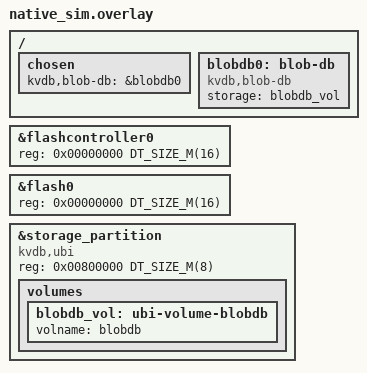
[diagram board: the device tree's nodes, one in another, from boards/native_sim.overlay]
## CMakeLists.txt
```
# Copyright (c) 2026
# SPDX-License-Identifier: Apache-2.0

cmake_minimum_required(VERSION 3.20.0)
find_package(Zephyr REQUIRED HINTS $ENV{ZEPHYR_BASE})
project(blob_db_contract_test)

# The model containers are the executable form of the L1 sufficiency proof
# (doc/layers/l1_model_container.md, l1_model_container_list.md). They are
# built here, not in lib/, because they are test/proof artifacts, not
# shipped code.
target_sources(app PRIVATE
	src/main.c
	src/model_container_map.c
	src/list.c
	src/model_container_list.c
)
target_include_directories(app PRIVATE src)
```

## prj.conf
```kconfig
CONFIG_ZTEST=y
# blob_db is switched on by the kvdb,blob-db node in boards/<board>.overlay.
CONFIG_BLOB_ROOTREG=y

# Compaction nests two 4 KB scratch buffers under a 4 KB bucket buffer;
# bump stacks to fit (same as the L1 unit suite).
CONFIG_MAIN_STACK_SIZE=32768
CONFIG_ZTEST_STACK_SIZE=32768
CONFIG_LOG=y
```

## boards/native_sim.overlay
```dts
/*
 * 16 MB sim-flash with an 8 MB storage_partition at offset 0x800000 — matches
 * the app and the L1 unit suite so blob_db sees the full multi-bucket layout.
 */

&flashcontroller0 {
	reg = <0x00000000 DT_SIZE_M(16)>;
};

&flash0 {
	reg = <0x00000000 DT_SIZE_M(16)>;
};

&storage_partition {
	/* A UBI device with one volume, which blob_db lives on. Keep
	 * "zephyr,mapped-partition": it is what makes the node a partition on
	 * native_sim.
	 */
	compatible = "kvdb,ubi", "zephyr,mapped-partition";
	reg = <0x00800000 DT_SIZE_M(8)>;

	volumes {
		blobdb_vol: ubi-volume-blobdb {
			volname = "blobdb";
		};
	};
};

/*
 * The blob_db store on the volume above. No "automount": the suite mounts,
 * formats and unmounts the store itself.
 */
/ {
	chosen {
		kvdb,blob-db = &blobdb0;
	};

	blobdb0: blob-db {
		compatible = "kvdb,blob-db";
		storage = <&blobdb_vol>;
	};
};
```

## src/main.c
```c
/*
 * Copyright (c) 2026
 * SPDX-License-Identifier: Apache-2.0
 *
 * L1 contract acceptance suite — drives the model container
 * (doc/layers/l1_model_container.md) end-to-end on native_sim to PROVE the
 * whole concept:
 *
 *   - single-integer reachability (P5): the container is re-opened after every
 *     remount from nothing but id = 1 — the root registry lives there and
 *     maps MC_ROOTREG_KEY to the list root;
 *   - crash-safety (P7): at every step of every reference-graph mutation, a
 *     crash + remount + recovery yields the complete old OR complete new
 *     mapping — never torn, never dangling;
 *   - no permanent leak (P7 must): after recovery the live blob count is
 *     EXACTLY the structural minimum (root + intent + 2 per entry).
 *
 * Crashes are injected at blob_db-operation boundaries: a mutation stops after
 * a chosen step (MC_STOPPED), then we unmount/remount and mc_open() runs
 * recovery from that exact point — matching the crash tables in §8.
 */

#include <errno.h>
#include <stdint.h>
#include <string.h>

#include <zephyr/ztest.h>

#include <app/lib/blob_db.h>
#include <app/lib/rootreg.h>

#include "model_container_map.h"

/* This suite is the container's CLIENT — it owns root-id persistence
 * (l1_root_registry.md §2) and registers the container under its key. */
#define MC_ROOTREG_KEY  ROOTREG_KEY(0x4d435f4d /* 'MC_M': model container, map */, 0)

/* Structural blob floor: the root registry (id = 1) + the list root + the
 * intent blob. Each live entry adds exactly two blobs (key + value). "No
 * leak" == live count matches this formula exactly. */
#define STRUCT_BLOBS  3

static void assert_no_leak(void)
{
	size_t entries;

	zassert_ok(mc_entry_count(&entries));
	zassert_equal(blob_db_count(), STRUCT_BLOBS + 2 * entries,
		      "leak: live blobs=%zu, expected=%zu (entries=%zu)",
		      blob_db_count(), STRUCT_BLOBS + 2 * entries, entries);
}

/* Client-side open: bootstrap the registry, resolve (or register) the
 * container's root id, hand it to the container. This is the l1½ pattern
 * every real client follows. */
static void open_container(void)
{
	uint64_t root;

	zassert_ok(rootreg_init());
	zassert_ok(rootreg_get_or_create(MC_ROOTREG_KEY, &root));
	zassert_ok(mc_open(root), "open/recovery failed");
}

/* Power-cut simulation: drop the mount and bring it back. The client
 * re-derives the entire container from id = 1 (registry -> list root) and
 * mc_open() runs intent recovery. */
static void crash_and_recover(void)
{
	zassert_ok(blob_db_unmount());
	zassert_ok(blob_db_mount());
	open_container();
}

/* Wipe to a virgin store and create an empty container. */
static void fresh_container(void)
{
	zassert_ok(blob_db_format());
	open_container();   /* virgin -> bootstrap registry + create */
}

static void before(void *f)
{
	ARG_UNUSED(f);
	mc_fail_after(MC_STEP_NONE, 0);
	mc_fail_key_read(0);
	blob_db_unmount();
	zassert_ok(blob_db_mount());
	fresh_container();
}

static void after(void *f)
{
	ARG_UNUSED(f);
	blob_db_unmount();
}

ZTEST_SUITE(blob_db_contract, NULL, NULL, before, after, NULL);

static int get_str(const char *key, char *out, size_t out_sz)
{
	size_t got;
	int rc = mc_get(key, out, out_sz, &got);

	if (rc == 0) {
		out[got] = '\0';
	}
	return rc;
}

/* --- basic flow (§3), completed mutations ------------------------------ */

ZTEST(blob_db_contract, test_empty_container)
{
	char buf[16];

	zassert_equal(get_str("foo", buf, sizeof(buf)), -ENOENT);
	assert_no_leak();
}

ZTEST(blob_db_contract, test_insert_lookup)
{
	zassert_ok(mc_set("foo", "bar", 3, MC_STEP_NONE));

	char buf[16];

	zassert_ok(get_str("foo", buf, sizeof(buf)));
	zassert_str_equal(buf, "bar");
	assert_no_leak();
}

ZTEST(blob_db_contract, test_overwrite)
{
	zassert_ok(mc_set("foo", "bar", 3, MC_STEP_NONE));
	zassert_ok(mc_set("foo", "bazzz", 5, MC_STEP_NONE));

	char buf[16];

	zassert_ok(get_str("foo", buf, sizeof(buf)));
	zassert_str_equal(buf, "bazzz");
	assert_no_leak();   /* old value blob reclaimed — count unchanged */
}

ZTEST(blob_db_contract, test_delete)
{
	zassert_ok(mc_set("foo", "bar", 3, MC_STEP_NONE));
	zassert_ok(mc_del("foo", MC_STEP_NONE));

	char buf[16];

	zassert_equal(get_str("foo", buf, sizeof(buf)), -ENOENT);
	assert_no_leak();   /* back to root + intent only */
}

/* --- single-integer reachability across remount ------------------------ */

ZTEST(blob_db_contract, test_multikey_persist_and_reopen)
{
	zassert_ok(mc_set("alpha", "1", 1, MC_STEP_NONE));
	zassert_ok(mc_set("beta", "22", 2, MC_STEP_NONE));
	zassert_ok(mc_set("gamma", "333", 3, MC_STEP_NONE));

	/* Reboot: the ONLY thing that persists is the integer 1. */
	crash_and_recover();

	char buf[16];

	zassert_ok(get_str("alpha", buf, sizeof(buf)));
	zassert_str_equal(buf, "1");
	zassert_ok(get_str("beta", buf, sizeof(buf)));
	zassert_str_equal(buf, "22");
	zassert_ok(get_str("gamma", buf, sizeof(buf)));
	zassert_str_equal(buf, "333");

	size_t entries;

	zassert_ok(mc_entry_count(&entries));
	zassert_equal(entries, 3);
	assert_no_leak();
}

/* --- crash tables (§8): recovery is correct AND leak-free -------------- */

struct crash_case {
	enum mc_crash_point cp;
	bool committed;
};

/* §8.1 Insert: committed once the list image is swapped (COMMIT). */
ZTEST(blob_db_contract, test_insert_crash_table)
{
	const struct crash_case cases[] = {
		{ MC_STEP_STAGE,   false },
		{ MC_STEP_PREPARE, false },
		{ MC_STEP_COMMIT,  true  },
		{ MC_STEP_CLEANUP, true  },
		{ MC_STEP_NONE,    true  },
	};

	for (size_t i = 0; i < ARRAY_SIZE(cases); i++) {
		fresh_container();

		int rc = mc_set("foo", "bar", 3, cases[i].cp);

		if (cases[i].cp == MC_STEP_NONE) {
			zassert_ok(rc);
		} else {
			zassert_equal(rc, MC_STOPPED, "case %zu", i);
		}

		crash_and_recover();

		char buf[16];

		if (cases[i].committed) {
			zassert_ok(get_str("foo", buf, sizeof(buf)),
				   "case %zu should be committed", i);
			zassert_str_equal(buf, "bar");
		} else {
			zassert_equal(get_str("foo", buf, sizeof(buf)), -ENOENT,
				      "case %zu should be rolled back", i);
		}
		assert_no_leak();   /* prepared-but-abandoned blobs reclaimed */
	}
}

/* §8.2 Overwrite (genuine value replacement): committed at COMMIT. */
ZTEST(blob_db_contract, test_overwrite_crash_table)
{
	const struct crash_case cases[] = {
		{ MC_STEP_STAGE,   false },
		{ MC_STEP_PREPARE, false },
		{ MC_STEP_COMMIT,  true  },
		{ MC_STEP_CLEANUP, true  },
		{ MC_STEP_NONE,    true  },
	};

	for (size_t i = 0; i < ARRAY_SIZE(cases); i++) {
		fresh_container();
		zassert_ok(mc_set("foo", "bar", 3, MC_STEP_NONE));   /* seed */

		int rc = mc_set("foo", "bazzz", 5, cases[i].cp);

		if (cases[i].cp == MC_STEP_NONE) {
			zassert_ok(rc);
		} else {
			zassert_equal(rc, MC_STOPPED, "case %zu", i);
		}

		crash_and_recover();

		char buf[16];

		zassert_ok(get_str("foo", buf, sizeof(buf)));
		zassert_str_equal(buf, cases[i].committed ? "bazzz" : "bar");

		size_t entries;

		zassert_ok(mc_entry_count(&entries));
		zassert_equal(entries, 1, "case %zu entries", i);
		assert_no_leak();   /* exactly one value blob survives */
	}
}

/* --- full-lifecycle cleanup: destroy + unregister ----------------------- */

/* Tear-down leaves the store at the absolute floor — ONLY the (empty-again)
 * registry survives — and a later open under the same key starts a brand-new
 * container on a fresh id (dead ids are never reused). */
ZTEST(blob_db_contract, test_destroy_and_unregister_cleanup)
{
	zassert_ok(mc_set("alpha", "1", 1, MC_STEP_NONE));
	zassert_ok(mc_set("beta", "22", 2, MC_STEP_NONE));
	zassert_ok(mc_set("gamma", "333", 3, MC_STEP_NONE));

	uint64_t old_root;

	zassert_ok(rootreg_get(MC_ROOTREG_KEY, &old_root));

	/* Cleanup: unset all keys + structure, then drop the registry entry
	 * (teardown BEFORE unregistration — registry §8). */
	zassert_ok(mc_destroy());
	zassert_ok(rootreg_unregister(MC_ROOTREG_KEY));

	/* Only the registry blob remains, and the container is truly gone. */
	zassert_equal(blob_db_count(), 1,
		      "want registry only, got %zu blobs", blob_db_count());
	zassert_false(blob_db_exists(old_root));

	char buf[8];

	zassert_equal(mc_get("alpha", buf, sizeof(buf), NULL), -ENODEV,
		      "container must be closed after destroy");

	/* Same key, fresh life: a new root id, an empty container. */
	open_container();

	uint64_t new_root;

	zassert_ok(rootreg_get(MC_ROOTREG_KEY, &new_root));
	zassert_not_equal(new_root, old_root, "dead ids must not be reused");
	zassert_equal(get_str("alpha", buf, sizeof(buf)), -ENOENT);
	assert_no_leak();
}

/* Destroy is re-runnable: a "crash" between destroy and unregister just
 * means the next open finds the registered id dead… which must NOT happen
 * silently — so the client contract is destroy-then-unregister with no
 * mutation in between. This test pins the safe rerun path instead: destroy
 * on an already-half-torn container (simulated by a double destroy cycle). */
ZTEST(blob_db_contract, test_destroy_empty_container)
{
	zassert_ok(mc_destroy());   /* no entries — deletes intent + root */
	zassert_ok(rootreg_unregister(MC_ROOTREG_KEY));
	zassert_equal(blob_db_count(), 1);

	open_container();           /* fresh container, fresh id */
	assert_no_leak();
}

/* --- create / destroy interrupted between root and intent ------------- */

/* The intent id the list root names, read straight from the root payload. */
static uint64_t root_intent_id(uint64_t root)
{
	uint8_t buf[CONFIG_BLOB_DB_MAX_PAYLOAD_LEN];
	size_t got;
	uint64_t id;

	zassert_ok(blob_db_get(root, buf, sizeof(buf), &got));
	memcpy(&id, buf, sizeof(id));
	return id;
}

/* Create commits the root first, naming an intent id it has not bound yet.
 * A crash right there must leave no residue: the next open gives the list
 * a fresh intent blob and never binds the one the root named. */
ZTEST(blob_db_contract, test_create_crash_before_intent)
{
	uint64_t root;

	zassert_ok(blob_db_format());
	zassert_ok(rootreg_init());
	zassert_ok(rootreg_get_or_create(MC_ROOTREG_KEY, &root));

	/* The state create leaves when it stops after its commit: an empty
	 * list naming an intent id that was allocated and never bound. */
	uint64_t unbound = blob_db_alloc_id();
	uint8_t img[12] = { 0 };

	zassert_not_equal(unbound, BLOB_DB_INVALID_ID);
	memcpy(img, &unbound, sizeof(unbound));
	zassert_ok(blob_db_update(root, img, sizeof(img)));

	crash_and_recover();

	zassert_false(blob_db_exists(unbound), "named intent id was bound");
	zassert_not_equal(root_intent_id(root), unbound);
	assert_no_leak();

	char buf[16];

	zassert_ok(mc_set("foo", "bar", 3, MC_STEP_NONE));
	zassert_ok(get_str("foo", buf, sizeof(buf)));
	zassert_str_equal(buf, "bar");
	assert_no_leak();
}

/* Destroy deletes the intent before the root. A crash between the two must
 * not leave the container unopenable: open repairs it and destroy reruns. */
ZTEST(blob_db_contract, test_destroy_crash_before_root)
{
	uint64_t root;

	zassert_ok(mc_set("foo", "bar", 3, MC_STEP_NONE));
	zassert_ok(rootreg_get(MC_ROOTREG_KEY, &root));

	/* Intent gone, root still bound — as when destroy stops between the
	 * two. (Destroy would have deleted the entries too; open does not
	 * care, and the rerun tolerates either.) */
	zassert_ok(blob_db_delete(root_intent_id(root)));

	crash_and_recover();

	zassert_ok(mc_destroy());
	zassert_ok(rootreg_unregister(MC_ROOTREG_KEY));
	zassert_equal(blob_db_count(), 1,
		      "want registry only, got %zu blobs", blob_db_count());
}

/* --- an unreadable key is not an absent key ---------------------------- */

/* Lookups skip only a key that answers -ENOENT. Any other read error
 * reaches the caller before anything is written — above all it never
 * turns an overwrite into the insert of a second entry for the key. */
ZTEST(blob_db_contract, test_key_read_error_propagates)
{
	char buf[16];
	size_t n;

	zassert_ok(mc_set("foo", "bar", 3, MC_STEP_NONE));

	mc_fail_key_read(-EIO);
	zassert_equal(mc_set("foo", "baz", 3, MC_STEP_NONE), -EIO);
	zassert_ok(mc_entry_count(&n));
	zassert_equal(n, 1, "an unreadable key was inserted again");
	zassert_ok(get_str("foo", buf, sizeof(buf)));
	zassert_str_equal(buf, "bar");
	assert_no_leak();

	mc_fail_key_read(-EIO);
	zassert_equal(get_str("foo", buf, sizeof(buf)), -EIO);

	mc_fail_key_read(-EIO);
	zassert_equal(mc_del("foo", MC_STEP_NONE), -EIO);
	zassert_ok(get_str("foo", buf, sizeof(buf)));
	zassert_str_equal(buf, "bar");
	assert_no_leak();
}

/* --- direct id-1 binding ------------------------------------------------ */

/* A client without a registry may build the list at BLOB_DB_ROOT_ID itself.
 * That id is never unbound — a fresh store binds it empty — so an empty
 * payload must read as "create now", and destroy must reset it to empty
 * instead of deleting it. */
ZTEST(blob_db_contract, test_direct_root_binding)
{
	char buf[16];

	zassert_ok(blob_db_format());   /* id 1 bound, empty; no registry */
	zassert_ok(mc_open(BLOB_DB_ROOT_ID));
	zassert_ok(mc_set("foo", "bar", 3, MC_STEP_NONE));

	zassert_ok(blob_db_unmount());
	zassert_ok(blob_db_mount());
	zassert_ok(mc_open(BLOB_DB_ROOT_ID));
	zassert_ok(get_str("foo", buf, sizeof(buf)));
	zassert_str_equal(buf, "bar");
	/* id 1 (list root) + intent + key + value */
	zassert_equal(blob_db_count(), 4, "got %zu blobs", blob_db_count());

	zassert_ok(mc_destroy());
	zassert_true(blob_db_exists(BLOB_DB_ROOT_ID));
	zassert_equal(blob_db_count(), 1, "got %zu blobs", blob_db_count());

	zassert_ok(mc_open(BLOB_DB_ROOT_ID));   /* fresh container */
	zassert_equal(get_str("foo", buf, sizeof(buf)), -ENOENT);
	zassert_equal(blob_db_count(), 2, "got %zu blobs", blob_db_count());
}

/* A root whose payload is not shaped like a list is refused, and leaves
 * the container closed. */
ZTEST(blob_db_contract, test_malformed_root_refused)
{
	uint64_t id = blob_db_alloc_id();
	char buf[16];

	zassert_not_equal(id, BLOB_DB_INVALID_ID);
	zassert_ok(blob_db_update(id, "xyz", 3));
	zassert_equal(mc_open(id), -EIO);
	zassert_equal(get_str("foo", buf, sizeof(buf)), -ENODEV);
}

/* --- recovery touches only the ids the intent names -------------------- */

/* A second structure in the same store, registered under its own key. */
#define OTHER_ROOTREG_KEY  ROOTREG_KEY(0x4f544852 /* 'OTHR' */, 0)

/* Firmware opens stores lazily, so after a reboot another client may
 * allocate and bind blobs BEFORE this container's mc_open() runs recovery.
 * Those blobs have ids above anything the interrupted mutation allocated,
 * and the container's list does not reference them. Rolling back must still
 * leave them alone: recovery deletes only what its intent named. */
ZTEST(blob_db_contract, test_rollback_spares_other_store)
{
	zassert_equal(mc_set("foo", "bar", 3, MC_STEP_PREPARE), MC_STOPPED);

	/* Reboot, but let another store come up and write first. */
	zassert_ok(blob_db_unmount());
	zassert_ok(blob_db_mount());
	zassert_ok(rootreg_init());

	uint64_t other;

	zassert_ok(rootreg_get_or_create(OTHER_ROOTREG_KEY, &other));
	zassert_ok(blob_db_update(other, "cfg", 3));

	/* Only now is the container opened, and its insert rolled back. */
	open_container();

	char buf[16];
	size_t got;

	zassert_equal(get_str("foo", buf, sizeof(buf)), -ENOENT);
	zassert_ok(blob_db_get(other, buf, sizeof(buf), &got),
		   "recovery deleted another store's blob");
	zassert_equal(got, 3);
	zassert_mem_equal(buf, "cfg", 3);

	/* No leak either: the container's floor plus the other store's root. */
	zassert_equal(blob_db_count(), STRUCT_BLOBS + 1,
		      "live blobs=%zu, expected=%d", blob_db_count(),
		      STRUCT_BLOBS + 1);
}

/* A full list is refused before anything is written: nothing to undo, and
 * nothing left behind. */
ZTEST(blob_db_contract, test_failed_set_leaks_nothing)
{
	char key[8];
	int rc;
	size_t n = 0;

	do {
		snprintk(key, sizeof(key), "k%zu", n++);
		rc = mc_set(key, "v", 1, MC_STEP_NONE);
	} while (rc == 0);

	zassert_equal(rc, -ENOSPC);
	assert_no_leak();

	/* The container still works, and a later mutation leaks nothing. */
	zassert_ok(mc_del("k0", MC_STEP_NONE));
	zassert_ok(mc_set("late", "v", 1, MC_STEP_NONE));
	assert_no_leak();
}

/* --- clean failures (§5 abort path), no remount ----------------------- */

/* A step that fails without a power cut aborts through the same recovery a
 * remount runs: rolled back (error returned) before COMMIT, finished (0
 * returned) after it. Either way nothing leaks, without remounting. */
ZTEST(blob_db_contract, test_failed_mutation_aborts_cleanly)
{
	const struct crash_case cases[] = {
		{ MC_STEP_STAGE,   false },
		{ MC_STEP_PREPARE, false },
		{ MC_STEP_COMMIT,  true  },
		{ MC_STEP_CLEANUP, true  },
	};
	char buf[16];

	for (size_t i = 0; i < ARRAY_SIZE(cases); i++) {
		const bool done = cases[i].committed;

		/* Insert. */
		fresh_container();
		mc_fail_after(cases[i].cp, -EIO);
		zassert_equal(mc_set("foo", "bar", 3, MC_STEP_NONE),
			      done ? 0 : -EIO, "insert case %zu", i);
		if (done) {
			zassert_ok(get_str("foo", buf, sizeof(buf)));
			zassert_str_equal(buf, "bar");
		} else {
			zassert_equal(get_str("foo", buf, sizeof(buf)), -ENOENT);
		}
		assert_no_leak();

		/* Overwrite. */
		fresh_container();
		zassert_ok(mc_set("foo", "bar", 3, MC_STEP_NONE));
		mc_fail_after(cases[i].cp, -EIO);
		zassert_equal(mc_set("foo", "bazzz", 5, MC_STEP_NONE),
			      done ? 0 : -EIO, "overwrite case %zu", i);
		zassert_ok(get_str("foo", buf, sizeof(buf)));
		zassert_str_equal(buf, done ? "bazzz" : "bar");
		assert_no_leak();

		/* Delete. */
		fresh_container();
		zassert_ok(mc_set("foo", "bar", 3, MC_STEP_NONE));
		mc_fail_after(cases[i].cp, -EIO);
		zassert_equal(mc_del("foo", MC_STEP_NONE),
			      done ? 0 : -EIO, "delete case %zu", i);
		zassert_equal(get_str("foo", buf, sizeof(buf)),
			      done ? -ENOENT : 0);
		assert_no_leak();

		/* The container keeps working after the abort. */
		zassert_ok(mc_set("next", "v", 1, MC_STEP_NONE));
		assert_no_leak();
	}
}

/* An interrupted mutation that nobody recovered yet (no remount) is
 * finished by the next mutation before it stages, and by destroy before it
 * deletes, so its prepared blobs are never stranded. */
ZTEST(blob_db_contract, test_staged_intent_finished_before_next_mutation)
{
	zassert_equal(mc_set("foo", "bar", 3, MC_STEP_PREPARE), MC_STOPPED);
	zassert_ok(mc_set("other", "v", 1, MC_STEP_NONE));

	char buf[16];

	zassert_equal(get_str("foo", buf, sizeof(buf)), -ENOENT);
	assert_no_leak();

	zassert_equal(mc_set("foo", "bar", 3, MC_STEP_PREPARE), MC_STOPPED);
	zassert_ok(mc_destroy());
	zassert_ok(rootreg_unregister(MC_ROOTREG_KEY));
	zassert_equal(blob_db_count(), 1,
		      "want registry only, got %zu blobs", blob_db_count());
}

/* §8.3 Delete: committed once the entry is unlinked (COMMIT). */
ZTEST(blob_db_contract, test_delete_crash_table)
{
	const struct crash_case cases[] = {
		{ MC_STEP_STAGE,   false },
		{ MC_STEP_PREPARE, false },
		{ MC_STEP_COMMIT,  true  },
		{ MC_STEP_CLEANUP, true  },
		{ MC_STEP_NONE,    true  },
	};

	for (size_t i = 0; i < ARRAY_SIZE(cases); i++) {
		fresh_container();
		zassert_ok(mc_set("foo", "bar", 3, MC_STEP_NONE));   /* seed */

		int rc = mc_del("foo", cases[i].cp);

		if (cases[i].cp == MC_STEP_NONE) {
			zassert_ok(rc);
		} else {
			zassert_equal(rc, MC_STOPPED, "case %zu", i);
		}

		crash_and_recover();

		char buf[16];

		if (cases[i].committed) {
			zassert_equal(get_str("foo", buf, sizeof(buf)), -ENOENT,
				      "case %zu should be deleted", i);
		} else {
			zassert_ok(get_str("foo", buf, sizeof(buf)),
				   "case %zu should be intact", i);
			zassert_str_equal(buf, "bar");
		}
		assert_no_leak();   /* orphaned key/value blobs reclaimed */
	}
}
```

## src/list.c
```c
/*
 * Copyright (c) 2026
 * SPDX-License-Identifier: Apache-2.0
 *
 * L1 contract acceptance suite, second model container: the doubly linked
 * list (doc/layers/l1_model_container_list.md). Same proof as main.c, for a
 * structure whose every structural mutation changes two existing i-nodes:
 *
 *   - single-integer reachability (P5): reopened after every remount from
 *     id = 1, where the root registry maps MCL_ROOTREG_KEY to the list root;
 *   - crash-safety (P7): at every step of every insert and remove, a crash +
 *     remount + recovery yields the complete old OR complete new list, read
 *     forwards AND backwards — the back chain always mirrors the forward one;
 *   - no permanent leak (P7 must): after recovery the live blob count is
 *     EXACTLY root registry + root + intent + 2 per node.
 */

#include <errno.h>
#include <stdint.h>
#include <string.h>

#include <zephyr/ztest.h>

#include <app/lib/blob_db.h>
#include <app/lib/rootreg.h>

#include "model_container_list.h"

#define MCL_ROOTREG_KEY  ROOTREG_KEY(0x4d435f4c /* 'MC_L': model container, list */, 0)
#define OTHER_ROOTREG_KEY  ROOTREG_KEY(0x4f544852 /* 'OTHR' */, 0)

/* Root registry (id = 1) + list root + intent. Each node adds two blobs:
 * the node and its value. */
#define STRUCT_BLOBS  3

static void open_list(void)
{
	uint64_t root;

	zassert_ok(rootreg_init());
	zassert_ok(rootreg_get_or_create(MCL_ROOTREG_KEY, &root));
	zassert_ok(mcl_open(root), "open/recovery failed");
}

static void crash_and_recover(void)
{
	zassert_ok(blob_db_unmount());
	zassert_ok(blob_db_mount());
	open_list();
}

static void fresh_list(void)
{
	mcl_fail_after(MCL_STEP_NONE, 0);
	zassert_ok(blob_db_format());
	open_list();
}

static void before(void *f)
{
	ARG_UNUSED(f);
	blob_db_unmount();
	zassert_ok(blob_db_mount());
	fresh_list();
}

static void after(void *f)
{
	ARG_UNUSED(f);
	blob_db_unmount();
}

ZTEST_SUITE(blob_db_contract_list, NULL, NULL, before, after, NULL);

/* Values in these tests are single characters, so a whole list reads as a
 * string: "abc" is a -> b -> c. */
static char val_of(uint64_t id)
{
	char v[4];
	size_t got;

	zassert_ok(mcl_get(id, v, sizeof(v), &got));
	zassert_equal(got, 1);
	return v[0];
}

/* The list reads `want` forwards and backwards, the back chain mirrors the
 * forward one node by node, and nothing leaked. */
static void expect_list(const char *want, const char *ctx)
{
	size_t n = strlen(want);
	size_t count;
	uint64_t id = 0;

	for (size_t i = 0; i < n; i++) {
		zassert_ok(mcl_next(id, &id));
		zassert_not_equal(id, 0, "%s: list ends at %zu, want \"%s\"",
				  ctx, i, want);
		zassert_equal(val_of(id), want[i], "%s: forward [%zu], want \"%s\"",
			      ctx, i, want);
	}
	zassert_ok(mcl_next(id, &id));
	zassert_equal(id, 0, "%s: list longer than \"%s\"", ctx, want);

	for (size_t i = n; i-- > 0;) {
		zassert_ok(mcl_prev(id, &id));
		zassert_not_equal(id, 0, "%s: back chain ends early", ctx);
		zassert_equal(val_of(id), want[i], "%s: backward [%zu], want \"%s\"",
			      ctx, i, want);
	}
	zassert_ok(mcl_prev(id, &id));
	zassert_equal(id, 0, "%s: back chain longer than \"%s\"", ctx, want);

	zassert_ok(mcl_check(&count), "%s: links disagree", ctx);
	zassert_equal(count, n);
	zassert_equal(blob_db_count(), STRUCT_BLOBS + 2 * n,
		      "%s: leak: live blobs=%zu, expected=%zu", ctx,
		      blob_db_count(), STRUCT_BLOBS + 2 * n);
}

/* Append each character of `vals` as a node; ids[i] is the i-th node. */
static void seed(const char *vals, uint64_t *ids)
{
	for (size_t i = 0; vals[i] != '\0'; i++) {
		zassert_ok(mcl_insert_before(0, &vals[i], 1, &ids[i],
					     MCL_STEP_NONE));
	}
}

/* --- basic operations ------------------------------------------------- */

ZTEST(blob_db_contract_list, test_empty_list)
{
	uint64_t id;

	zassert_ok(mcl_next(0, &id));
	zassert_equal(id, 0);
	zassert_ok(mcl_prev(0, &id));
	zassert_equal(id, 0);
	expect_list("", "empty");
}

ZTEST(blob_db_contract_list, test_insert_everywhere)
{
	uint64_t ids[3];
	uint64_t x;

	seed("abc", ids);                       /* push_back x3 */
	expect_list("abc", "seed");
	zassert_ok(mcl_insert_after(0, "z", 1, NULL, MCL_STEP_NONE));
	expect_list("zabc", "push_front");
	zassert_ok(mcl_insert_after(ids[0], "x", 1, &x, MCL_STEP_NONE));
	expect_list("zaxbc", "insert_after a");
	zassert_ok(mcl_insert_before(ids[2], "y", 1, NULL, MCL_STEP_NONE));
	expect_list("zaxbyc", "insert_before c");
	zassert_ok(mcl_insert_after(ids[2], "w", 1, NULL, MCL_STEP_NONE));
	expect_list("zaxbycw", "insert_after tail");
	zassert_ok(mcl_insert_before(x, "v", 1, NULL, MCL_STEP_NONE));
	expect_list("zavxbycw", "insert_before x");
}

ZTEST(blob_db_contract_list, test_remove_everywhere)
{
	uint64_t ids[5];

	seed("abcde", ids);
	zassert_ok(mcl_remove(ids[2], MCL_STEP_NONE));
	expect_list("abde", "remove middle");
	zassert_ok(mcl_remove(ids[0], MCL_STEP_NONE));
	expect_list("bde", "remove head");
	zassert_ok(mcl_remove(ids[4], MCL_STEP_NONE));
	expect_list("bd", "remove tail");
	zassert_ok(mcl_remove(ids[1], MCL_STEP_NONE));
	zassert_ok(mcl_remove(ids[3], MCL_STEP_NONE));
	expect_list("", "remove only");

	/* A removed node is no handle any more. */
	zassert_equal(mcl_remove(ids[3], MCL_STEP_NONE), -ENOENT);
	zassert_equal(mcl_insert_after(ids[3], "q", 1, NULL, MCL_STEP_NONE),
		      -ENOENT);
	expect_list("", "after stale handles");
}

/* Overwriting a value does not change the reference graph: one in-place
 * update, no new blob, nothing to recover. */
ZTEST(blob_db_contract_list, test_set_in_place)
{
	uint64_t ids[3];

	seed("abc", ids);
	zassert_ok(mcl_set(ids[1], "B", 1));
	expect_list("aBc", "set");
}

ZTEST(blob_db_contract_list, test_persist_and_reopen)
{
	uint64_t ids[4];

	seed("abcd", ids);
	zassert_ok(mcl_remove(ids[1], MCL_STEP_NONE));

	crash_and_recover();   /* only the integer 1 persists */

	expect_list("acd", "reopen");
	zassert_ok(mcl_insert_after(ids[0], "b", 1, NULL, MCL_STEP_NONE));
	expect_list("abcd", "after reopen");
}

/* A node id from another structure, or the list's own root, is not a node
 * of this list: writes refuse it and change nothing. */
ZTEST(blob_db_contract_list, test_foreign_ids_refused)
{
	uint64_t ids[2];
	uint64_t root;
	uint64_t other;
	/* Shaped like a node, and claiming to follow the head. */
	uint64_t fake[3];

	seed("ab", ids);
	zassert_ok(rootreg_get(MCL_ROOTREG_KEY, &root));
	zassert_ok(rootreg_get_or_create(OTHER_ROOTREG_KEY, &other));
	fake[0] = ids[0];
	fake[1] = ids[1];
	fake[2] = ids[1];
	zassert_ok(blob_db_update(other, fake, sizeof(fake)));

	zassert_equal(mcl_remove(other, MCL_STEP_NONE), -ENOENT);
	zassert_equal(mcl_remove(root, MCL_STEP_NONE), -ENOENT);
	zassert_equal(mcl_insert_after(other, "x", 1, NULL, MCL_STEP_NONE),
		      -ENOENT);
	zassert_equal(mcl_set(other, "x", 1), -ENOENT);

	zassert_ok(rootreg_unregister(OTHER_ROOTREG_KEY));
	zassert_ok(blob_db_delete(other));
	expect_list("ab", "foreign");
}

/* --- crash tables (§6): recovery is correct AND leak-free -------------- */

enum op_kind { INS_AFTER, INS_BEFORE, REMOVE };

/* One structural mutation: on a list seeded with `seed`, insert "n" next to
 * (or remove) seed node `at` (-1: the root's end). */
struct op_case {
	const char *name;
	const char *seed;
	enum op_kind kind;
	int at;
	const char *after;
};

static const struct op_case ops[] = {
	{ "push_front empty", "",    INS_AFTER,  -1, "n"    },
	{ "push_front",       "abc", INS_AFTER,  -1, "nabc" },
	{ "insert_after mid", "abc", INS_AFTER,   0, "anbc" },
	{ "insert_before",    "abc", INS_BEFORE,  2, "abnc" },
	{ "push_back",        "abc", INS_BEFORE, -1, "abcn" },
	{ "remove head",      "abc", REMOVE,      0, "bc"   },
	{ "remove mid",       "abc", REMOVE,      1, "ac"   },
	{ "remove tail",      "abc", REMOVE,      2, "ab"   },
	{ "remove only",      "a",   REMOVE,      0, ""     },
};

/* An insert that returns 0 hands back the new node's id, also when it
 * finished through the abort path: check it names the "n" node. */
static int run_op(const struct op_case *op, const uint64_t *ids,
		  enum mcl_crash_point cp)
{
	uint64_t at = op->at < 0 ? 0 : ids[op->at];
	uint64_t nid = 0;
	int rc;

	switch (op->kind) {
	case INS_AFTER:
		rc = mcl_insert_after(at, "n", 1, &nid, cp);
		break;
	case INS_BEFORE:
		rc = mcl_insert_before(at, "n", 1, &nid, cp);
		break;
	default:
		return mcl_remove(at, cp);
	}
	if (rc == 0) {
		zassert_equal(val_of(nid), 'n', "%s: wrong id handed back",
			      op->name);
	}
	return rc;
}

struct crash_case {
	enum mcl_crash_point cp;
	bool committed;
};

/* Committed once the forward link is swapped (COMMIT). */
static const struct crash_case points[] = {
	{ MCL_STEP_STAGE,   false },
	{ MCL_STEP_PREPARE, false },
	{ MCL_STEP_COMMIT,  true  },
	{ MCL_STEP_REPAIR,  true  },
	{ MCL_STEP_CLEANUP, true  },
	{ MCL_STEP_NONE,    true  },
};

ZTEST(blob_db_contract_list, test_crash_table)
{
	for (size_t i = 0; i < ARRAY_SIZE(ops); i++) {
		for (size_t j = 0; j < ARRAY_SIZE(points); j++) {
			uint64_t ids[3];
			char ctx[48];

			snprintk(ctx, sizeof(ctx), "%s, crash point %d",
				 ops[i].name, points[j].cp);
			fresh_list();
			seed(ops[i].seed, ids);

			int rc = run_op(&ops[i], ids, points[j].cp);

			zassert_equal(rc, points[j].cp == MCL_STEP_NONE ?
					  0 : MCL_STOPPED, "%s: rc %d", ctx, rc);

			crash_and_recover();
			expect_list(points[j].committed ? ops[i].after :
				    ops[i].seed, ctx);
		}
	}
}

/* --- clean failures (abort path), no remount -------------------------- */

ZTEST(blob_db_contract_list, test_failed_mutation_aborts_cleanly)
{
	for (size_t i = 0; i < ARRAY_SIZE(ops); i++) {
		for (size_t j = 0; j < ARRAY_SIZE(points); j++) {
			uint64_t ids[3];
			char ctx[48];

			if (points[j].cp == MCL_STEP_NONE) {
				continue;
			}
			snprintk(ctx, sizeof(ctx), "%s, fail after %d",
				 ops[i].name, points[j].cp);
			fresh_list();
			seed(ops[i].seed, ids);

			mcl_fail_after(points[j].cp, -EIO);
			zassert_equal(run_op(&ops[i], ids, MCL_STEP_NONE),
				      points[j].committed ? 0 : -EIO, "%s", ctx);
			expect_list(points[j].committed ? ops[i].after :
				    ops[i].seed, ctx);

			/* The list keeps working after the abort. */
			size_t len = strlen(points[j].committed ?
					    ops[i].after : ops[i].seed);
			size_t count;

			zassert_ok(mcl_insert_before(0, "t", 1, NULL,
						     MCL_STEP_NONE));
			zassert_ok(mcl_check(&count));
			zassert_equal(count, len + 1, "%s", ctx);
		}
	}
}

/* --- the two chains between COMMIT and REPAIR -------------------------- */

/* The forward chain is right at every instant: before the commit it does
 * not show the new node, after it it does — with no recovery run. The back
 * chain is stale in between, so mcl_prev finishes the mutation first. */
ZTEST(blob_db_contract_list, test_forward_chain_always_right)
{
	uint64_t ids[2];
	uint64_t id;

	seed("ab", ids);
	zassert_equal(mcl_insert_before(0, "n", 1, NULL, MCL_STEP_PREPARE),
		      MCL_STOPPED);
	zassert_ok(mcl_next(ids[1], &id));
	zassert_equal(id, 0, "uncommitted node visible");

	fresh_list();
	seed("ab", ids);
	zassert_equal(mcl_insert_before(0, "n", 1, NULL, MCL_STEP_COMMIT),
		      MCL_STOPPED);
	zassert_ok(mcl_next(ids[1], &id));
	zassert_not_equal(id, 0, "committed node not visible forwards");
	zassert_equal(val_of(id), 'n');

	/* Backwards from the end: the tail is still "b" on flash until the
	 * repair; mcl_prev runs it and answers "n". */
	zassert_ok(mcl_prev(0, &id));
	zassert_equal(val_of(id), 'n', "stale back link surfaced");
	expect_list("abn", "after prev");
}

/* An interrupted mutation nobody recovered yet (no remount) is finished by
 * the next mutation before it stages, and by destroy before it deletes. */
ZTEST(blob_db_contract_list, test_staged_intent_finished_before_next_mutation)
{
	uint64_t ids[2];

	seed("ab", ids);
	zassert_equal(mcl_insert_after(ids[0], "n", 1, NULL, MCL_STEP_COMMIT),
		      MCL_STOPPED);
	zassert_ok(mcl_insert_before(ids[1], "m", 1, NULL, MCL_STEP_NONE));
	expect_list("anmb", "finished, then inserted");

	zassert_equal(mcl_insert_before(0, "x", 1, NULL, MCL_STEP_PREPARE),
		      MCL_STOPPED);
	zassert_ok(mcl_destroy());
	zassert_ok(rootreg_unregister(MCL_ROOTREG_KEY));
	zassert_equal(blob_db_count(), 1,
		      "want registry only, got %zu blobs", blob_db_count());
}

/* Firmware opens stores lazily: another client may bind blobs after the
 * reboot and before this list's recovery runs. Rolling back must leave
 * them alone. */
ZTEST(blob_db_contract_list, test_rollback_spares_other_store)
{
	uint64_t other;
	char buf[8];
	size_t got;

	zassert_equal(mcl_insert_after(0, "n", 1, NULL, MCL_STEP_PREPARE),
		      MCL_STOPPED);

	zassert_ok(blob_db_unmount());
	zassert_ok(blob_db_mount());
	zassert_ok(rootreg_init());
	zassert_ok(rootreg_get_or_create(OTHER_ROOTREG_KEY, &other));
	zassert_ok(blob_db_update(other, "cfg", 3));

	open_list();

	zassert_ok(blob_db_get(other, buf, sizeof(buf), &got),
		   "recovery deleted another store's blob");
	zassert_equal(got, 3);
	zassert_mem_equal(buf, "cfg", 3);
	zassert_equal(blob_db_count(), STRUCT_BLOBS + 1);
}

/* --- teardown ----------------------------------------------------------- */

ZTEST(blob_db_contract_list, test_destroy_and_unregister_cleanup)
{
	uint64_t ids[3];
	uint64_t old_root;
	uint64_t new_root;
	uint64_t id;

	seed("abc", ids);
	zassert_ok(rootreg_get(MCL_ROOTREG_KEY, &old_root));
	zassert_ok(mcl_destroy());
	zassert_ok(rootreg_unregister(MCL_ROOTREG_KEY));

	zassert_equal(blob_db_count(), 1,
		      "want registry only, got %zu blobs", blob_db_count());
	zassert_false(blob_db_exists(old_root));
	zassert_equal(mcl_next(0, &id), -ENODEV);

	open_list();
	zassert_ok(rootreg_get(MCL_ROOTREG_KEY, &new_root));
	zassert_not_equal(new_root, old_root, "dead ids must not be reused");
	expect_list("", "new life");
}

/* Destroy deletes from the tail backwards. A crash part-way leaves a
 * forward prefix with a dangling tail; a rerun after reopen finishes it. */
ZTEST(blob_db_contract_list, test_destroy_rerun_after_crash)
{
	uint64_t ids[3];
	uint64_t node[3];   /* prev, next, vid */
	size_t got;

	seed("abc", ids);

	/* What destroy does first, then the power goes: the tail's value and
	 * the tail node. */
	zassert_ok(blob_db_get(ids[2], node, sizeof(node), &got));
	zassert_equal(got, sizeof(node));
	zassert_ok(blob_db_delete(node[2]));
	zassert_ok(blob_db_delete(ids[2]));

	crash_and_recover();
	zassert_ok(mcl_destroy());
	zassert_ok(rootreg_unregister(MCL_ROOTREG_KEY));
	zassert_equal(blob_db_count(), 1,
		      "want registry only, got %zu blobs", blob_db_count());
}
```

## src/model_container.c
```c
/*
 * Copyright (c) 2026
 * SPDX-License-Identifier: Apache-2.0
 *
 * Model container — executable form of doc/layers/l1_model_container.md.
 * Built on nothing but the blob_db L1 contract. See model_container.h.
 */

#include <errno.h>
#include <string.h>

#include <zephyr/logging/log.h>

#include <app/lib/blob_db.h>

#include "model_container.h"

LOG_MODULE_REGISTER(model_container, LOG_LEVEL_INF);

#define MC_MAX_ENTRIES  15   /* (256 - 12) / 16, one payload */
#define MC_MAX_DEL       4
#define MC_MAX_KEY      32
#define MC_MAX_VAL      64

/* The list root id, handed in by the client on mc_open(). How it is
 * persisted (root registry, direct id-1 binding) is the client's business. */
static uint64_t mc_root;

/* ---- RAM shapes (parsed from flash payloads) -------------------------- */

struct mc_list {
	uint64_t intent_id;
	uint32_t count;
	struct {
		uint64_t kid;
		uint64_t vid;
	} e[MC_MAX_ENTRIES];
};

struct mc_intent {
	uint64_t w;                 /* watermark; 0 == no mutation in flight */
	uint32_t ndel;
	uint64_t del[MC_MAX_DEL];
};

static bool mc_ready;

/* ---- (de)serialization ------------------------------------------------ */

static size_t list_serialize(const struct mc_list *l, uint8_t *buf)
{
	size_t off = 0;

	memcpy(buf + off, &l->intent_id, sizeof(l->intent_id));
	off += sizeof(l->intent_id);
	memcpy(buf + off, &l->count, sizeof(l->count));
	off += sizeof(l->count);
	for (uint32_t i = 0; i < l->count; i++) {
		memcpy(buf + off, &l->e[i].kid, 8);
		off += 8;
		memcpy(buf + off, &l->e[i].vid, 8);
		off += 8;
	}
	return off;
}

static int list_load(struct mc_list *l)
{
	uint8_t buf[CONFIG_BLOB_DB_MAX_PAYLOAD_LEN];
	size_t got;
	int rc = blob_db_get(mc_root, buf, sizeof(buf), &got);

	if (rc < 0) {
		return rc;
	}
	memset(l, 0, sizeof(*l));
	size_t off = 0;

	memcpy(&l->intent_id, buf + off, 8);
	off += 8;
	memcpy(&l->count, buf + off, 4);
	off += 4;
	if (l->count > MC_MAX_ENTRIES) {
		return -EIO;
	}
	for (uint32_t i = 0; i < l->count; i++) {
		memcpy(&l->e[i].kid, buf + off, 8);
		off += 8;
		memcpy(&l->e[i].vid, buf + off, 8);
		off += 8;
	}
	return 0;
}

static int list_store(const struct mc_list *l)
{
	uint8_t buf[CONFIG_BLOB_DB_MAX_PAYLOAD_LEN];
	size_t len = list_serialize(l, buf);

	return blob_db_update(mc_root, buf, len);
}

static int intent_load(uint64_t intent_id, struct mc_intent *in)
{
	uint8_t buf[CONFIG_BLOB_DB_MAX_PAYLOAD_LEN];
	size_t got;
	int rc = blob_db_get(intent_id, buf, sizeof(buf), &got);

	if (rc < 0) {
		return rc;
	}
	memset(in, 0, sizeof(*in));
	if (got == 0) {
		return 0;   /* freshly allocated, treated as empty */
	}
	size_t off = 0;

	memcpy(&in->w, buf + off, 8);
	off += 8;
	memcpy(&in->ndel, buf + off, 4);
	off += 4;
	if (in->ndel > MC_MAX_DEL) {
		return -EIO;
	}
	for (uint32_t i = 0; i < in->ndel; i++) {
		memcpy(&in->del[i], buf + off, 8);
		off += 8;
	}
	return 0;
}

static int intent_store(uint64_t intent_id, const struct mc_intent *in)
{
	uint8_t buf[CONFIG_BLOB_DB_MAX_PAYLOAD_LEN];
	size_t off = 0;

	memcpy(buf + off, &in->w, 8);
	off += 8;
	memcpy(buf + off, &in->ndel, 4);
	off += 4;
	for (uint32_t i = 0; i < in->ndel; i++) {
		memcpy(buf + off, &in->del[i], 8);
		off += 8;
	}
	return blob_db_update(intent_id, buf, off);
}

static int intent_clear(uint64_t intent_id)
{
	struct mc_intent empty = { 0 };

	return intent_store(intent_id, &empty);
}

/* ---- helpers ---------------------------------------------------------- */

static bool list_refs_id(const struct mc_list *l, uint64_t id)
{
	for (uint32_t i = 0; i < l->count; i++) {
		if (l->e[i].kid == id || l->e[i].vid == id) {
			return true;
		}
	}
	return false;
}

static bool list_refs_any_ge(const struct mc_list *l, uint64_t w)
{
	for (uint32_t i = 0; i < l->count; i++) {
		if (l->e[i].kid >= w || l->e[i].vid >= w) {
			return true;
		}
	}
	return false;
}

/* Find the entry index for `key`, or -1. */
static int list_find(const struct mc_list *l, const char *key, size_t klen)
{
	for (uint32_t i = 0; i < l->count; i++) {
		uint8_t kb[MC_MAX_KEY];
		size_t got;

		if (blob_db_get(l->e[i].kid, kb, sizeof(kb), &got) < 0) {
			continue;   /* dangling ref — treated as absent (§7) */
		}
		if (got == klen && memcmp(kb, key, klen) == 0) {
			return (int)i;
		}
	}
	return -1;
}

/* ---- rollback scan (collect-then-delete; iterate is read-only, D5) ----- */

struct rollback_ctx {
	const struct mc_list *l;
	uint64_t intent_id;
	uint64_t w;
	uint64_t victims[MC_MAX_ENTRIES * 2 + MC_MAX_DEL];
	size_t   nvictims;
};

static int rollback_collect(uint64_t id, const void *p, size_t len, void *user)
{
	struct rollback_ctx *c = user;

	ARG_UNUSED(p);
	ARG_UNUSED(len);
	if (id < c->w) {
		return 0;   /* below watermark — not this mutation's */
	}
	if (id == mc_root || id == c->intent_id) {
		return 0;   /* structural */
	}
	if (list_refs_id(c->l, id)) {
		return 0;   /* linked — keep */
	}
	if (c->nvictims < ARRAY_SIZE(c->victims)) {
		c->victims[c->nvictims++] = id;
	}
	return 0;
}

/* ---- recovery (l1_model_container.md §6) ------------------------------ */

static int mc_recover(struct mc_list *l)
{
	struct mc_intent in;
	int rc = intent_load(l->intent_id, &in);

	if (rc < 0) {
		return rc;
	}
	if (in.w == 0) {
		return 0;   /* empty intent — nothing in flight */
	}

	LOG_INF("recover: interrupted mutation W=%llu ndel=%u",
		(unsigned long long)in.w, in.ndel);

	bool committed = list_refs_any_ge(l, in.w);

	if (!committed && in.ndel > 0) {
		/* Pure-delete case: committed iff the list no longer
		 * references any del[] id. */
		bool any_del_referenced = false;

		for (uint32_t i = 0; i < in.ndel; i++) {
			if (list_refs_id(l, in.del[i])) {
				any_del_referenced = true;
				break;
			}
		}
		committed = !any_del_referenced;
	}

	if (committed) {
		/* ROLL FORWARD: delete every id in del[] (tolerate -ENOENT). */
		for (uint32_t i = 0; i < in.ndel; i++) {
			rc = blob_db_delete(in.del[i]);
			if (rc < 0 && rc != -ENOENT) {
				return rc;
			}
		}
	} else {
		/* ROLL BACK: delete bound ids >= W the list does not link. */
		struct rollback_ctx c = {
			.l = l, .intent_id = l->intent_id, .w = in.w,
		};

		rc = blob_db_iterate(rollback_collect, &c);
		if (rc < 0) {
			return rc;
		}
		for (size_t i = 0; i < c.nvictims; i++) {
			rc = blob_db_delete(c.victims[i]);
			if (rc < 0 && rc != -ENOENT) {
				return rc;
			}
		}
	}

	return intent_clear(l->intent_id);   /* CLEAR — last, idempotent */
}

/* ---- create (virgin store, basic flow §3.1 + registry §7) ------------- */

static int mc_create(void)
{
	/* mc_root is allocated but not yet bound (the client's durable record
	 * of it — e.g. a registry entry — is the creation intent). Allocate
	 * and bind the intent blob, then bind the initial list image; the
	 * final update is the commit that makes the container exist. */
	uint64_t intent_id = blob_db_alloc_id();
	struct mc_intent empty = { 0 };
	int rc = intent_store(intent_id, &empty);   /* bind intent blob */

	if (rc < 0) {
		return rc;
	}

	struct mc_list l = { .intent_id = intent_id, .count = 0 };

	return list_store(&l);   /* COMMIT — container exists at mc_root */
}

/* ---- public API ------------------------------------------------------- */

int mc_open(uint64_t root_id)
{
	if (root_id == 0) {
		return -EINVAL;
	}
	mc_root = root_id;

	uint8_t probe[4];
	size_t got;
	int rc = blob_db_get(mc_root, probe, sizeof(probe), &got);

	/* Allocated-but-unbound root (the client's record exists, the blob
	 * doesn't — registry §7 "creation in progress"): finish it now. */
	if (rc == -ENOENT) {
		rc = mc_create();
		if (rc < 0) {
			return rc;
		}
		mc_ready = true;
		return 0;
	}
	/* -ENOMEM just means the list is bigger than the probe buffer —
	 * that's fine, it exists. Any other negative is a real error. */
	if (rc < 0 && rc != -ENOMEM) {
		return rc;
	}

	struct mc_list l;

	rc = list_load(&l);
	if (rc < 0) {
		return rc;
	}
	rc = mc_recover(&l);
	if (rc < 0) {
		return rc;
	}
	mc_ready = true;
	return 0;
}

int mc_get(const char *key, void *out, size_t out_sz, size_t *out_len)
{
	if (!mc_ready) {
		return -ENODEV;
	}

	struct mc_list l;
	int rc = list_load(&l);

	if (rc < 0) {
		return rc;
	}

	int idx = list_find(&l, key, strlen(key));

	if (idx < 0) {
		return -ENOENT;
	}
	return blob_db_get(l.e[idx].vid, out, out_sz, out_len);
}

int mc_entry_count(size_t *out)
{
	struct mc_list l;
	int rc = list_load(&l);

	if (rc < 0) {
		return rc;
	}
	*out = l.count;
	return 0;
}

/* STAGE helper: build+store the intent, honoring the crash point. */
#define STOP_IF(cp)  do { if (crash_at == (cp)) { return MC_STOPPED; } } while (0)

int mc_set(const char *key, const void *val, size_t vlen,
	   enum mc_crash_point crash_at)
{
	if (!mc_ready) {
		return -ENODEV;
	}
	size_t klen = strlen(key);

	if (klen == 0 || klen > MC_MAX_KEY || vlen > MC_MAX_VAL) {
		return -EINVAL;
	}

	struct mc_list l;
	int rc = list_load(&l);

	if (rc < 0) {
		return rc;
	}

	int idx = list_find(&l, key, klen);

	/* step 0: watermark (RAM only). */
	uint64_t w = blob_db_alloc_id();

	struct mc_intent in = { .w = w, .ndel = 0 };

	if (idx >= 0) {
		/* overwrite: the old value blob dies on commit (§8.2). */
		in.ndel = 1;
		in.del[0] = l.e[idx].vid;
	}

	/* step 1: STAGE. */
	rc = intent_store(l.intent_id, &in);
	if (rc < 0) {
		return rc;
	}
	STOP_IF(MC_STEP_STAGE);

	/* step 2: PREPARE — bind the new blobs (ids > W, unreferenced). */
	uint64_t vid2 = blob_db_alloc_id();

	rc = blob_db_update(vid2, val, vlen);
	if (rc < 0) {
		return rc;
	}

	uint64_t kid = 0;

	if (idx < 0) {
		kid = blob_db_alloc_id();
		rc = blob_db_update(kid, key, klen);
		if (rc < 0) {
			return rc;
		}
	}
	STOP_IF(MC_STEP_PREPARE);

	/* step 3: COMMIT — swap the list image (linearization point). */
	if (idx >= 0) {
		l.e[idx].vid = vid2;
	} else {
		if (l.count >= MC_MAX_ENTRIES) {
			return -ENOSPC;
		}
		l.e[l.count].kid = kid;
		l.e[l.count].vid = vid2;
		l.count++;
	}
	rc = list_store(&l);
	if (rc < 0) {
		return rc;
	}
	STOP_IF(MC_STEP_COMMIT);

	/* step 4: CLEANUP — delete superseded blobs. */
	for (uint32_t i = 0; i < in.ndel; i++) {
		rc = blob_db_delete(in.del[i]);
		if (rc < 0 && rc != -ENOENT) {
			return rc;
		}
	}
	STOP_IF(MC_STEP_CLEANUP);

	/* step 5: CLEAR. */
	return intent_clear(l.intent_id);
}

int mc_destroy(void)
{
	if (!mc_ready) {
		return -ENODEV;
	}

	struct mc_list l;
	int rc = list_load(&l);

	if (rc < 0) {
		return rc;
	}

	/* Delete leaves first, the root last, so a crash anywhere leaves a
	 * re-runnable state: the root still loads, dangling entry refs read
	 * as absent, and every delete below tolerates -ENOENT on rerun. */
	for (uint32_t i = 0; i < l.count; i++) {
		rc = blob_db_delete(l.e[i].kid);
		if (rc < 0 && rc != -ENOENT) {
			return rc;
		}
		rc = blob_db_delete(l.e[i].vid);
		if (rc < 0 && rc != -ENOENT) {
			return rc;
		}
	}
	rc = blob_db_delete(l.intent_id);
	if (rc < 0 && rc != -ENOENT) {
		return rc;
	}
	rc = blob_db_delete(mc_root);
	if (rc < 0 && rc != -ENOENT) {
		return rc;
	}

	mc_ready = false;
	mc_root = 0;
	return 0;
}

int mc_del(const char *key, enum mc_crash_point crash_at)
{
	if (!mc_ready) {
		return -ENODEV;
	}

	struct mc_list l;
	int rc = list_load(&l);

	if (rc < 0) {
		return rc;
	}

	int idx = list_find(&l, key, strlen(key));

	if (idx < 0) {
		return -ENOENT;
	}

	/* step 0: watermark. */
	uint64_t w = blob_db_alloc_id();
	struct mc_intent in = {
		.w = w, .ndel = 2,
		.del = { l.e[idx].kid, l.e[idx].vid },
	};

	/* step 1: STAGE. */
	rc = intent_store(l.intent_id, &in);
	if (rc < 0) {
		return rc;
	}
	STOP_IF(MC_STEP_STAGE);

	/* (delete creates nothing — no PREPARE.) */
	STOP_IF(MC_STEP_PREPARE);

	/* step 2: COMMIT — unlink the entry. */
	l.e[idx] = l.e[l.count - 1];
	l.count--;
	rc = list_store(&l);
	if (rc < 0) {
		return rc;
	}
	STOP_IF(MC_STEP_COMMIT);

	/* step 3/4: CLEANUP — delete the now-unlinked blobs. */
	rc = blob_db_delete(in.del[0]);
	if (rc < 0 && rc != -ENOENT) {
		return rc;
	}
	rc = blob_db_delete(in.del[1]);
	if (rc < 0 && rc != -ENOENT) {
		return rc;
	}
	STOP_IF(MC_STEP_CLEANUP);

	/* step 5: CLEAR. */
	return intent_clear(l.intent_id);
}
```
